# 3061MNPICA register map
File version: 1.0
Registers are 32-bit, access per field, reset 0x0 unless marked. A register's access mark holds for its fields unless they carry their own. Offsets are from the block's base; [hi:lo] are bit positions; {n}, {i} and the like mark numbered series.

## CRG — CRG peripheral interface
Base 0x10000000
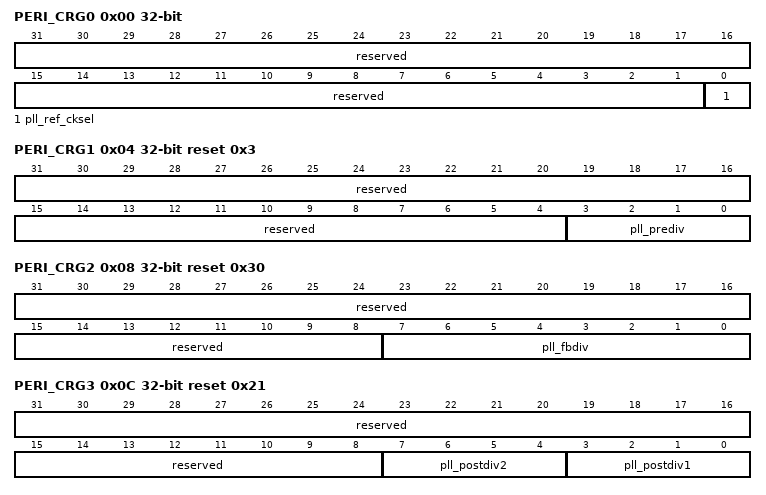
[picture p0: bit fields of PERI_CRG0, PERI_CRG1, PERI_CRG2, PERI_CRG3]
0x00 PERI_CRG0 — PLL配置寄存器0。
  [31:1] reserved ro — 保留
  [0] pll_ref_cksel rw — PLL输入参考时钟clk_pll_ref时钟源选择信号： 0：选择clk_hosc； 1：选择clk_xtal。
0x04 PERI_CRG1 reset 0x3 — PLL 配置寄存器 1。
  [31:4] reserved ro — 保留
  [3:0] pll_prediv rw — PLL内部前置分频器分频比： 0x0：1分频； 0x1：2分频； 0x2：3分频； 0x3：4分频； 0x4：5分频； 0x5：6分频； 0x6：7分频； 0x7：8分频； 其他：未使用。
0x08 PERI_CRG2 reset 0x30 — PLL 配置寄存器 2。
  [31:8] reserved ro — 保留
  [7:0] pll_fbdiv rw — PLL内部反馈分频器分频比： 0x00 - 0x06：6分频； 0x07 - 0x7F：7 - 127分频； 其他：未使用。
0x0C PERI_CRG3 reset 0x21 — PLL 配置寄存器 3。
  [31:8] reserved ro — 保留
  [7:4] pll_postdiv2 rw — PLL内部后置分频器分频比： 0x0：1分频； 0x1：2分频； 0x2：3分频； 0x3：4分频； 0x4：5分频； 0x5：6分频； 0x6：7分频； 0x7：8分频； 其他：未使用。
  [3:0] pll_postdiv1 rw — PLL内部后置分频器分频比： 0x0：1分频； 0x1：2分频； 0x2：3分频； 0x3：4分频； 0x4：5分频； 0x5：6分频； 0x6：7分频； 0x7：8分频； 其他：未使用。
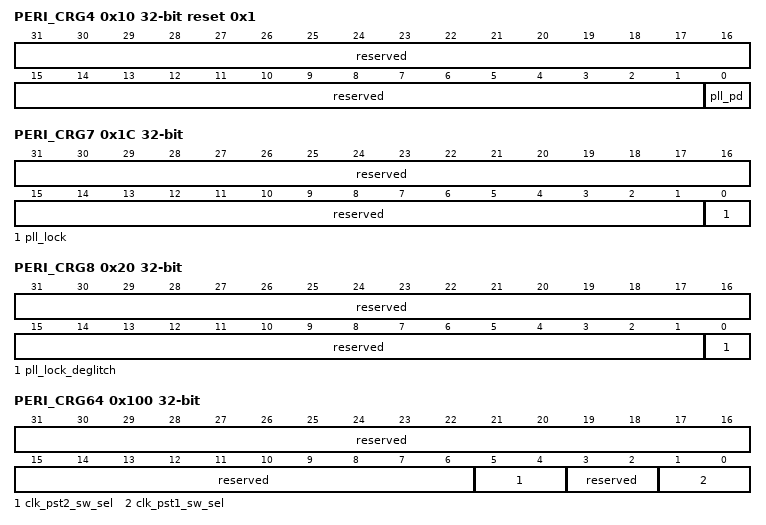
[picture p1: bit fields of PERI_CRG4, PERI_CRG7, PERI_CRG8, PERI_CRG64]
0x10 PERI_CRG4 reset 0x1 — PLL 配置寄存器 4。
  [31:1] reserved ro — 保留
  [0] pll_pd rw — PLL使能控制： 0：PLL上电使能； 1：PLL下电关闭。
0x1C PERI_CRG7 ro — PLL 输出时钟频率稳定标志寄存器。
  [31:1] reserved — 保留
  [0] pll_lock — PLL 时钟稳定标志位信号： 0：PLL 输出频率未稳定； 1：PLL 输出频率稳定。
0x20 PERI_CRG8 ro — pll输出lock去毛刺信号寄存器。
  [31:1] reserved — 保留
  [0] pll_lock_deglitch — pll lock硬件虑毛刺之后信号。
0x100 PERI_CRG64 — 系统时钟控制寄存器。
  [31:6] reserved ro — 保留
  [5:4] clk_pst2_sw_sel rw — clk_pst2_100m 时钟选择信号： 00：选择 clk_hosc； 01：选择 clk_xtal； 10：选择 clk_pll_pst2； 11：保留。
  [3:2] reserved ro — 保留
  [1:0] clk_pst1_sw_sel rw — hclk 时钟选择信号： 00：选择 clk_hosc； 01：选择 clk_xtal； 10：选择 clk_pll_pst1； 11：保留。
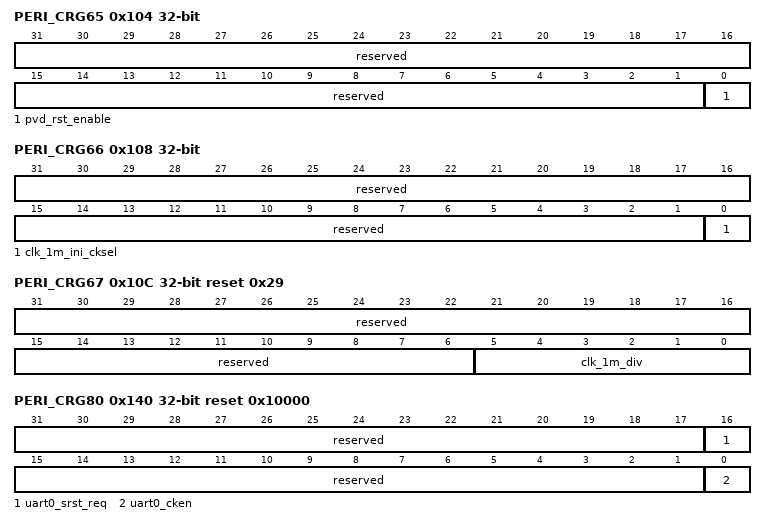
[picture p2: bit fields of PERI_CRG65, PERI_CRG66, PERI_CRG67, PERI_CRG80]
0x104 PERI_CRG65 — PVD复位控制寄存器。
  [31:1] reserved ro — 保留
  [0] pvd_rst_enable rw — pvd复位使能 0：不使能； 1：使能。
0x108 PERI_CRG66 — CLK_1M时钟源头选择控制寄存器。
  [31:1] reserved ro — 保留
  [0] clk_1m_ini_cksel rw — 1MHz 时钟和 clk_bg_chopper 时钟的源头 时钟选择信号： 0：选择 clk_hosc，默认； 1：选择 clk_xtal。
0x10C PERI_CRG67 reset 0x29 — CLK_1M时钟分频控制寄存器。
  [31:6] reserved ro — 保留
  [5:0] clk_1m_div rw — clk_1m时钟分频参数，配置范围为[0-63] 输出时钟频率为输入时钟频率/(clk_1m_div + 1)。 默认42分频，配'd29
0x140 PERI_CRG80 reset 0x10000 — uart0时钟及软复位控制寄存器。
  [31:17] reserved ro — 保留
  [16] uart0_srst_req rw — uart0软复位请求： 0：不复位； 1：复位。
  [15:1] reserved ro — 保留
  [0] uart0_cken rw — uart0时钟使能： 0：关闭； 1：打开。
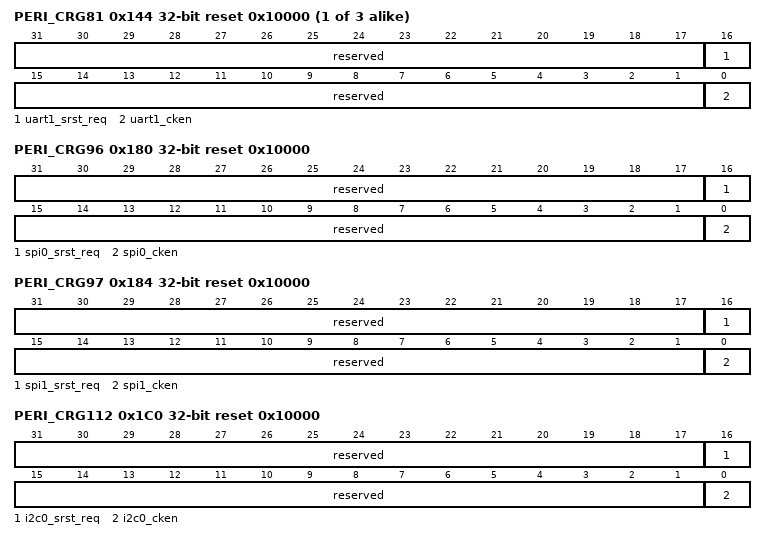
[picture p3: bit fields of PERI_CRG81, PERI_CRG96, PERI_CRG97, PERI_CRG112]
{0x0+4i} PERI_CRG{i} reset 0x10000 (i=81..83) — uart{i-80}时钟及软复位控制寄存器。
  [31:17] reserved ro — 保留
  [16] uart{i-80}_srst_req rw — uart{i-80}软复位请求： 0：不复位； 1：复位。
  [15:1] reserved ro — 保留
  [0] uart{i-80}_cken rw — uart{i-80}时钟使能： 0：关断； 1：打开。
0x180 PERI_CRG96 reset 0x10000 — spi0时钟及软复位控制寄存器。
  [31:17] reserved ro — 保留
  [16] spi0_srst_req rw — spi0软复位请求： 0：不复位； 1：复位。
  [15:1] reserved ro — 保留
  [0] spi0_cken rw — spi0时钟使能： 0：关断； 1：打开。
0x184 PERI_CRG97 reset 0x10000 — spi1时钟及软复位控制寄存器。
  [31:17] reserved ro — 保留
  [16] spi1_srst_req rw — spi1软复位请求： 0：不复位； 1：复位。
  [15:1] reserved ro — 保留
  [0] spi1_cken rw — spi1时钟使能： 0：关断； 1：打开。
0x1C0 PERI_CRG112 reset 0x10000 — i2c0时钟及软复位控制寄存器。
  [31:17] reserved ro — 保留
  [16] i2c0_srst_req rw — i2c0软复位请求： 0：不复位； 1：复位。
  [15:1] reserved ro — 保留
  [0] i2c0_cken rw — i2c0时钟使能： 0：关断； 1：打开。
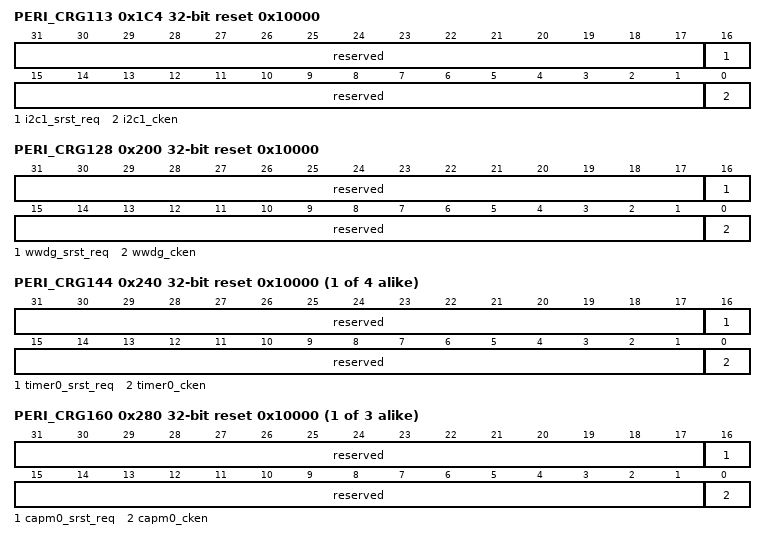
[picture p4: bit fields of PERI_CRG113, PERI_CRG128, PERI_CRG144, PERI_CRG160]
0x1C4 PERI_CRG113 reset 0x10000 — i2c1时钟及软复位控制寄存器。
  [31:17] reserved ro — 保留
  [16] i2c1_srst_req rw — i2c1软复位请求： 0：不复位； 1：复位。
  [15:1] reserved ro — 保留
  [0] i2c1_cken rw — i2c1时钟使能： 0：关断； 1：打开。
0x200 PERI_CRG128 reset 0x10000 — wwdg时钟及软复位控制寄存器。
  [31:17] reserved ro — 保留
  [16] wwdg_srst_req rw — wwdg软复位请求： 0：不复位； 1：复位。
  [15:1] reserved ro — 保留
  [0] wwdg_cken rw — wwdg时钟使能： 0：关断； 1：打开。
{0x0+4i} PERI_CRG{i} reset 0x10000 (i=144..147) — timer{i-144}时钟及软复位控制寄存器。
  [31:17] reserved ro — 保留
  [16] timer{i-144}_srst_req rw — timer{i-144}软复位请求： 0：不复位； 1：复位。
  [15:1] reserved ro — 保留
  [0] timer{i-144}_cken rw — timer{i-144}时钟使能： 0：关断； 1：打开。
{0x0+4i} PERI_CRG{i} reset 0x10000 (i=160..162) — capm{i-160}时钟及软复位控制寄存器。
  [31:17] reserved ro — 保留
  [16] capm{i-160}_srst_req rw — capm{i-160}软复位请求： 0：不复位； 1：复位。
  [15:1] reserved ro — 保留
  [0] capm{i-160}_cken rw — capm{i-160}时钟使能： 0：关断； 1：打开。
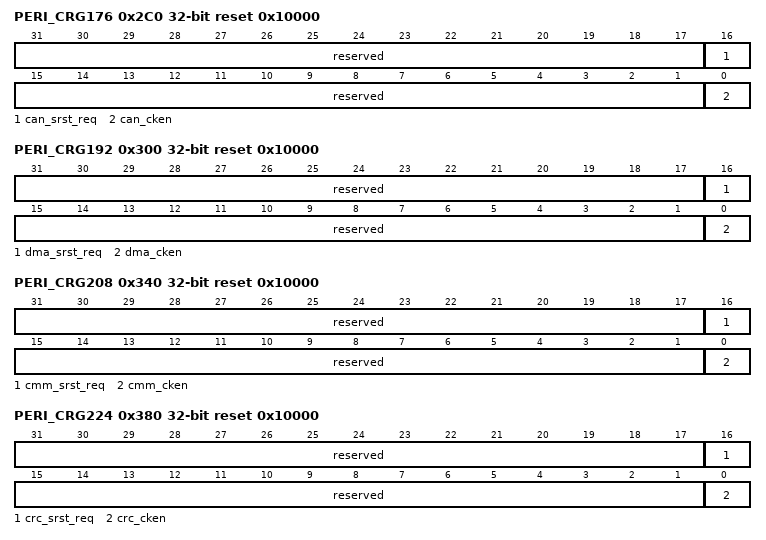
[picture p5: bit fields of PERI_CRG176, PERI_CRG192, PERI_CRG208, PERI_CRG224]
0x2C0 PERI_CRG176 reset 0x10000 — can时钟及软复位控制寄存器。
  [31:17] reserved ro — 保留
  [16] can_srst_req rw — can软复位请求： 0：不复位； 1：复位。
  [15:1] reserved ro — 保留
  [0] can_cken rw — can时钟使能： 0：关断； 1：打开。
0x300 PERI_CRG192 reset 0x10000 — dma时钟及软复位控制寄存器。
  [31:17] reserved ro — 保留
  [16] dma_srst_req rw — dma软复位请求： 0：不复位； 1：复位。
  [15:1] reserved ro — 保留
  [0] dma_cken rw — dma时钟使能： 0：关断； 1：打开。
0x340 PERI_CRG208 reset 0x10000 — cmm时钟及软复位控制寄存器。
  [31:17] reserved ro — 保留
  [16] cmm_srst_req rw — cmm软复位请求： 0：不复位； 1：复位。
  [15:1] reserved ro — 保留
  [0] cmm_cken rw — cmm时钟使能： 0：关断； 1：打开。
0x380 PERI_CRG224 reset 0x10000 — crc时钟及软复位控制寄存器。
  [31:17] reserved ro — 保留
  [16] crc_srst_req rw — crc软复位请求： 0：不复位； 1：复位。
  [15:1] reserved ro — 保留
  [0] crc_cken rw — crc时钟使能： 0：关断； 1：打开。
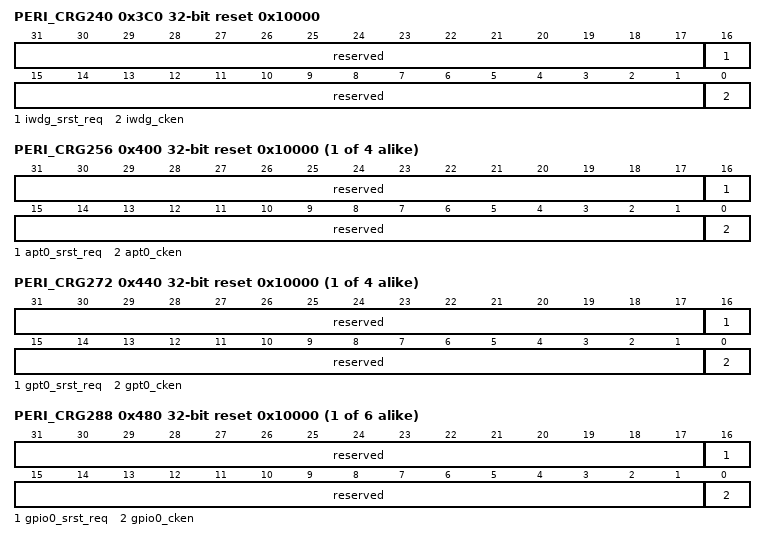
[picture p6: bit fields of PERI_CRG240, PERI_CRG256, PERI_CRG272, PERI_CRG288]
0x3C0 PERI_CRG240 reset 0x10000 — iwdg时钟及软复位控制寄存器。
  [31:17] reserved ro — 保留
  [16] iwdg_srst_req rw — iwdg软复位请求： 0：不复位； 1：复位。
  [15:1] reserved ro — 保留
  [0] iwdg_cken rw — iwdg时钟使能： 0：关断； 1：打开。
{0x0+4i} PERI_CRG{i} reset 0x10000 (i=256..259) — apt{i-256}时钟及软复位控制寄存器。
  [31:17] reserved ro — 保留
  [16] apt{i-256}_srst_req rw — apt{i-256}软复位请求： 0：不复位； 1：复位。
  [15:1] reserved ro — 保留
  [0] apt{i-256}_cken rw — apt{i-256}时钟使能： 0：关断； 1：打开。
{0x0+4i} PERI_CRG{i} reset 0x10000 (i=272..275) — gpt{i-272}时钟及软复位控制寄存器。
  [31:17] reserved ro — 保留
  [16] gpt{i-272}_srst_req rw — gpt{i-272}软复位请求： 0：不复位； 1：复位。
  [15:1] reserved ro — 保留
  [0] gpt{i-272}_cken rw — gpt{i-272}时钟使能： 0：关断； 1：打开。
{0x0+4i} PERI_CRG{i} reset 0x10000 (i=288..293) — gpio{i-288}时钟及软复位控制寄存器。
  [31:17] reserved ro — 保留
  [16] gpio{i-288}_srst_req rw — gpio{i-288}软复位请求： 0：不复位； 1：复位。
  [15:1] reserved ro — 保留
  [0] gpio{i-288}_cken rw — gpio{i-288}时钟使能： 0：关断； 1：打开。
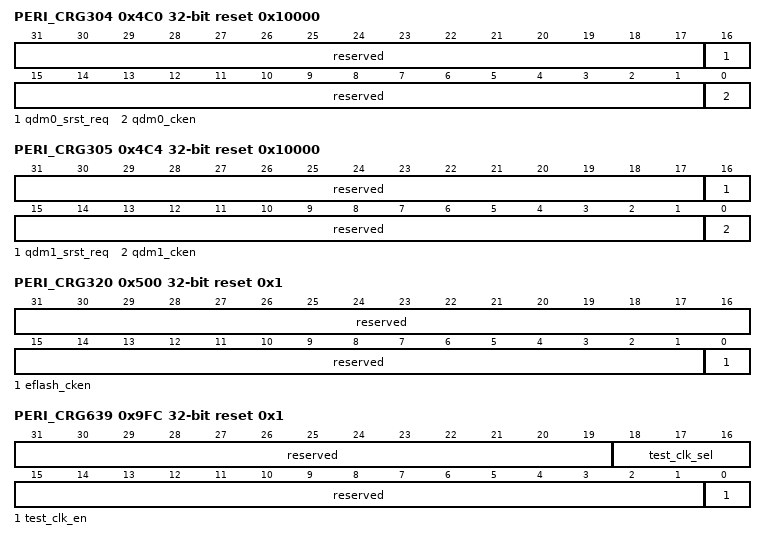
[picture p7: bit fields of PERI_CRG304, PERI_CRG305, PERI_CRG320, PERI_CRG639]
0x4C0 PERI_CRG304 reset 0x10000 — QDM0时钟及软复位控制寄存器。
  [31:17] reserved ro — 保留
  [16] qdm0_srst_req rw — qdm0软复位请求： 0：不复位； 1：复位。
  [15:1] reserved ro — 保留
  [0] qdm0_cken rw — qdm0时钟使能： 0：关断； 1：打开。
0x4C4 PERI_CRG305 reset 0x10000 — QDM1时钟及软复位控制寄存器。
  [31:17] reserved ro — 保留
  [16] qdm1_srst_req rw — qdm1软复位请求： 0：不复位； 1：复位。
  [15:1] reserved ro — 保留
  [0] qdm1_cken rw — qdm1时钟使能： 0：关断； 1：打开。
0x500 PERI_CRG320 reset 0x1 — flash时钟控制寄存器。
  [31:1] reserved ro — 保留
  [0] eflash_cken rw — eflash时钟使能： 0：关断； 1：打开。
0x9FC PERI_CRG639 reset 0x1 — TEST时钟选择控制寄存器。
  [31:19] reserved ro — 保留
  [18:16] test_clk_sel rw — test_clk时钟选择： 000：pll_pfd； 001：clk_hosc； 010：clk_losc； 011：clk_tcxo； 100：clk_bg_chopper； 101：clk_adc/4； 110：hclk/6; 111：clk_hosc_div.
  [15:1] reserved ro — 保留
  [0] test_clk_en rw — test_clk_en时钟观测使能信号。 0：不使能； 1：使能。
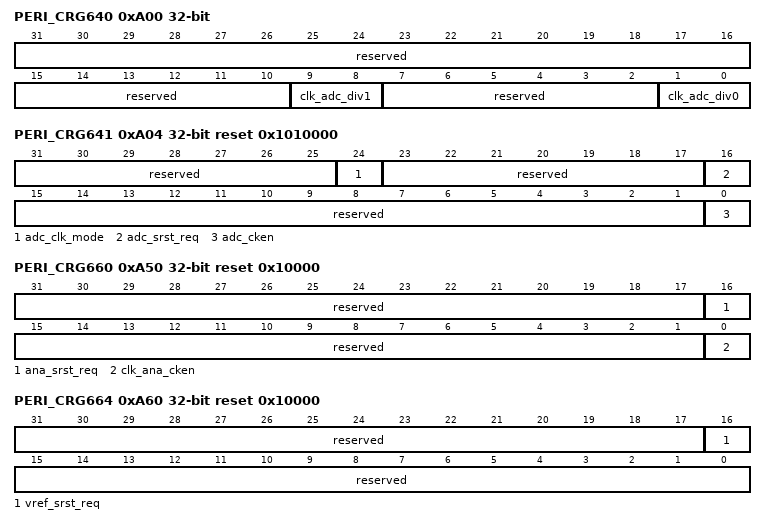
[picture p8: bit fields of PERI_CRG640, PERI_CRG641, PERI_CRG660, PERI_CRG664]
0xA00 PERI_CRG640 — ADC分频时钟配置寄存器。
  [31:10] reserved rw — 保留
  [9:8] clk_adc_div1 rw — clk_adc I1路时钟分频参数,配置范围[0-3]。 输出时钟频率为输入时钟频率/(clk_adc_div + 1)。 默认不分频,配0。
  [7:2] reserved ro — 保留
  [1:0] clk_adc_div0 rw — clk_adc I0路时钟分频参数,配置范围[0-3]。 输出时钟频率为输入时钟频率/(clk_adc_div + 1)。 默认不分频,配0。
0xA04 PERI_CRG641 reset 0x1010000 — ADC时钟及软复位控制寄存器。
  [31:25] reserved ro — 保留
  [24] adc_clk_mode rw — clk_adc时钟选择信号。 0：PLL FOUTPOSTDIV2出来100M时钟，默认； 1：主频时钟经过分频后的时钟。
  [23:17] reserved ro — 保留
  [16] adc_srst_req rw — adc软复位请求： 0：不复位； 1：复位。
  [15:1] reserved ro — 保留
  [0] adc_cken rw — adc时钟使能： 0：关断； 1：打开。
0xA50 PERI_CRG660 reset 0x10000 — ANA时钟控制寄存器。
  [31:17] reserved ro — 保留
  [16] ana_srst_req rw — ana软复位请求： 0：不复位； 1：复位。
  [15:1] reserved ro — 保留
  [0] clk_ana_cken rw — ana时钟使能： 0：关断； 1：打开。
0xA60 PERI_CRG664 reset 0x10000 — VREF软复位请求。
  [31:17] reserved ro — 保留
  [16] vref_srst_req rw — vref软复位请求： 0：不复位； 1：复位。
  [15:0] reserved ro — 保留
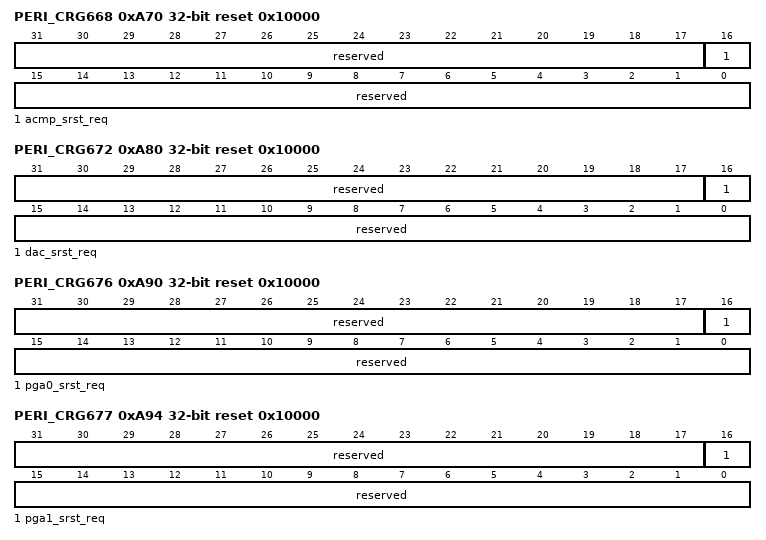
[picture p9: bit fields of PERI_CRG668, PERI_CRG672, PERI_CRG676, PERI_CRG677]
0xA70 PERI_CRG668 reset 0x10000 — ACMP软复位请求。
  [31:17] reserved ro — 保留
  [16] acmp_srst_req rw — acmp软复位请求： 0：不复位； 1：复位。
  [15:0] reserved ro — 保留
0xA80 PERI_CRG672 reset 0x10000 — DAC软复位请求。
  [31:17] reserved ro — 保留
  [16] dac_srst_req rw — dac软复位请求： 0：不复位； 1：复位。
  [15:0] reserved ro — 时钟门控保留
0xA90 PERI_CRG676 reset 0x10000 — PGA0软复位请求。
  [31:17] reserved ro — 保留
  [16] pga0_srst_req rw — pga0软复位请求： 0：不复位； 1：复位。
  [15:0] reserved ro — 保留
0xA94 PERI_CRG677 reset 0x10000 — PGA1软复位请求。
  [31:17] reserved ro — 保留
  [16] pga1_srst_req rw — pga1软复位请求： 0：不复位； 1：复位。
  [15:0] reserved ro — 保留
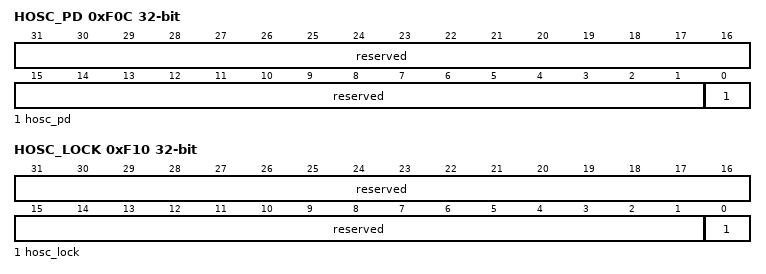
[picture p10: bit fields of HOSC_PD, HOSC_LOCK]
0xF0C HOSC_PD — HOSC配置寄存器。
  [31:1] reserved ro — 保留
  [0] hosc_pd rw — HOSC使能信号。 0：HOSC上电使能； 1：HOSC下电关闭。
0xF10 HOSC_LOCK ro — HOSC LOCK信号观测。
  [31:1] reserved — 保留
  [0] hosc_lock — HOSC时钟稳定标志位信号。 0：HOSC输出频率未稳定； 1：HOSC输出频率稳定。
